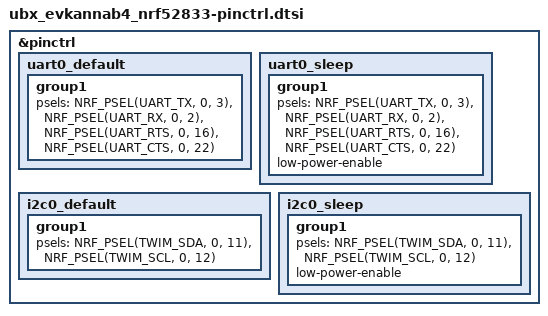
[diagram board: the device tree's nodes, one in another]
/*
 * Copyright (c) 2023 u-blox
 * SPDX-License-Identifier: Apache-2.0
 */
 
 &pinctrl {
	uart0_default: uart0_default {
		group1 {
			psels = <NRF_PSEL(UART_TX, 0, 3)>,
				<NRF_PSEL(UART_RX, 0, 2)>,
				<NRF_PSEL(UART_RTS, 0, 16)>,
				<NRF_PSEL(UART_CTS, 0, 22)>;
		};
	};

	uart0_sleep: uart0_sleep {
		group1 {
			psels = <NRF_PSEL(UART_TX, 0, 3)>,
				<NRF_PSEL(UART_RX, 0, 2)>,
				<NRF_PSEL(UART_RTS, 0, 16)>,
				<NRF_PSEL(UART_CTS, 0, 22)>;
			low-power-enable;
		};
	};

	i2c0_default: i2c0_default {
		group1 {
			psels = <NRF_PSEL(TWIM_SDA, 0, 11)>,
				<NRF_PSEL(TWIM_SCL, 0, 12)>;
		};
	};

	i2c0_sleep: i2c0_sleep {
		group1 {
			psels = <NRF_PSEL(TWIM_SDA, 0, 11)>,
				<NRF_PSEL(TWIM_SCL, 0, 12)>;
			low-power-enable;
		};
	};

};
